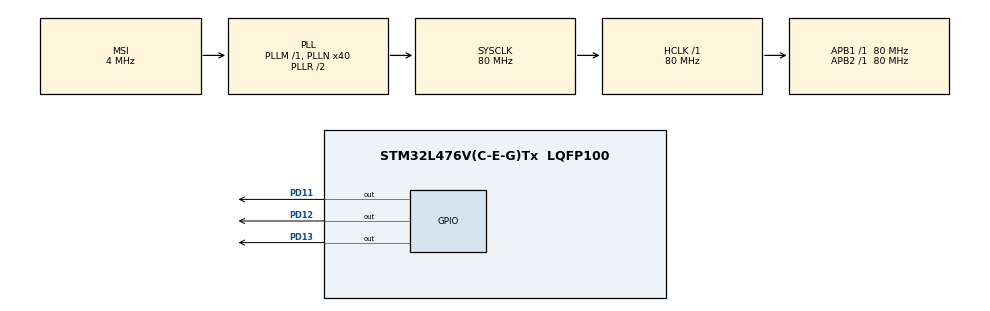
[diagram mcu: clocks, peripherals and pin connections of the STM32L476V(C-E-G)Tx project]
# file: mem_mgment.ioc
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FREERTOS.INCLUDE_xEventGroupSetBitFromISR=1
FREERTOS.INCLUDE_xTimerPendFunctionCall=1
FREERTOS.Tasks01=defaultTask,0,128,StartDefaultTask,Default,NULL,Dynamic,NULL,NULL
FREERTOS.configTOTAL_HEAP_SIZE=5000
FREERTOS.configUSE_NEWLIB_REENTRANT=0
FREERTOS.configUSE_TIMERS=1
Mcu.Family=STM32L4
Mcu.Name=STM32L476V(C-E-G)Tx
Mcu.Package=LQFP100
NVIC.PriorityGroup=NVIC_PRIORITYGROUP_4
NVIC.TIM1_UP_TIM16_IRQn=true\:0\:0\:false\:false\:true\:false\:false\:true
NVIC.TimeBase=TIM1_UP_TIM16_IRQn
NVIC.TimeBaseIP=TIM1
PD11.Signal=GPIO_Output
PD12.Signal=GPIO_Output
PD13.Signal=GPIO_Output
ProjectManager.HeapSize=0x200
ProjectManager.StackSize=0x400
ProjectManager.TargetToolchain=STM32CubeIDE
RCC.AHBFreq_Value=80000000
RCC.APB1Freq_Value=80000000
RCC.APB1TimFreq_Value=80000000
RCC.APB2Freq_Value=80000000
RCC.APB2TimFreq_Value=80000000
RCC.CortexFreq_Value=80000000
RCC.HCLKFreq_Value=80000000
RCC.HSE_VALUE=8000000
RCC.HSI_VALUE=16000000
RCC.LSE_VALUE=32768
RCC.MSI_VALUE=4000000
RCC.PLLN=40
RCC.SYSCLKFreq_VALUE=80000000
RCC.SYSCLKSource=RCC_SYSCLKSOURCE_PLLCLK
RCC.VCOOutputFreq_Value=160000000
VP_FREERTOS_VS_CMSIS_V1.Mode=CMSIS_V1
VP_SYS_VS_tim1.Mode=TIM1
board=custom

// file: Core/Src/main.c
/* USER CODE BEGIN Header */
/**
  ******************************************************************************
  * @file           : main.c
  * @brief          : Main program body
  ******************************************************************************
  * @attention
  *
  * <h2><center>&copy; Copyright (c) 2021 STMicroelectronics.
  * All rights reserved.</center></h2>
  *
  * This software component is licensed by ST under BSD 3-Clause license,
  * the "License"; You may not use this file except in compliance with the
  * License. You may obtain a copy of the License at:
  *                        opensource.org/licenses/BSD-3-Clause
  *
  ******************************************************************************
  */
/* USER CODE END Header */

#include "main.h"
#include "cmsis_os.h"
#include "gpio.h"

/* USER CODE BEGIN PV */
int A __attribute__((section(".ram2"))) = 10U;
/* USER CODE END PV */

void SystemClock_Config(void);
void MX_FREERTOS_Init(void);

int main(void)
{

  /* MCU Configuration--------------------------------------------------------*/

  /* Reset of all peripherals, Initializes the Flash interface and the Systick. */
  HAL_Init();

  /* Configure the system clock */
  SystemClock_Config();

  /* Initialize all configured peripherals */
  MX_GPIO_Init();
  /* USER CODE BEGIN 2 */
  A = 2;
  /* USER CODE END 2 */

  /* Call init function for freertos objects (in freertos.c) */
  MX_FREERTOS_Init();
  /* Start scheduler */
  osKernelStart();

  /* We should never get here as control is now taken by the scheduler */
  /* Infinite loop */
  while (1)
  {

  }
}

void SystemClock_Config(void)
{
  RCC_OscInitTypeDef RCC_OscInitStruct = {0};
  RCC_ClkInitTypeDef RCC_ClkInitStruct = {0};

  /** Initializes the CPU, AHB and APB busses clocks
  */
  RCC_OscInitStruct.OscillatorType = RCC_OSCILLATORTYPE_MSI;
  RCC_OscInitStruct.MSIState = RCC_MSI_ON;
  RCC_OscInitStruct.MSICalibrationValue = 0;
  RCC_OscInitStruct.MSIClockRange = RCC_MSIRANGE_6;
  RCC_OscInitStruct.PLL.PLLState = RCC_PLL_ON;
  RCC_OscInitStruct.PLL.PLLSource = RCC_PLLSOURCE_MSI;
  RCC_OscInitStruct.PLL.PLLM = 1;
  RCC_OscInitStruct.PLL.PLLN = 40;
  RCC_OscInitStruct.PLL.PLLP = RCC_PLLP_DIV7;
  RCC_OscInitStruct.PLL.PLLQ = RCC_PLLQ_DIV2;
  RCC_OscInitStruct.PLL.PLLR = RCC_PLLR_DIV2;
  if (HAL_RCC_OscConfig(&RCC_OscInitStruct) != HAL_OK)
  {
    Error_Handler();
  }
  /** Initializes the CPU, AHB and APB busses clocks
  */
  RCC_ClkInitStruct.ClockType = RCC_CLOCKTYPE_HCLK|RCC_CLOCKTYPE_SYSCLK
                              |RCC_CLOCKTYPE_PCLK1|RCC_CLOCKTYPE_PCLK2;
  RCC_ClkInitStruct.SYSCLKSource = RCC_SYSCLKSOURCE_PLLCLK;
  RCC_ClkInitStruct.AHBCLKDivider = RCC_SYSCLK_DIV1;
  RCC_ClkInitStruct.APB1CLKDivider = RCC_HCLK_DIV1;
  RCC_ClkInitStruct.APB2CLKDivider = RCC_HCLK_DIV1;

  if (HAL_RCC_ClockConfig(&RCC_ClkInitStruct, FLASH_LATENCY_4) != HAL_OK)
  {
    Error_Handler();
  }
  /** Configure the main internal regulator output voltage
  */
  if (HAL_PWREx_ControlVoltageScaling(PWR_REGULATOR_VOLTAGE_SCALE1) != HAL_OK)
  {
    Error_Handler();
  }
}

 /**
  * @brief  Period elapsed callback in non blocking mode
  * @note   This function is called  when TIM1 interrupt took place, inside
  * HAL_TIM_IRQHandler(). It makes a direct call to HAL_IncTick() to increment
  * a global variable "uwTick" used as application time base.
  * @param  htim : TIM handle
  * @retval None
  */
void HAL_TIM_PeriodElapsedCallback(TIM_HandleTypeDef *htim)
{
  if (htim->Instance == TIM1) {
    HAL_IncTick();
  }
}

void Error_Handler(void)
{
}

/************************ (C) COPYRIGHT STMicroelectronics *****END OF FILE****/

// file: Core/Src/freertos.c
/* USER CODE BEGIN Header */
/**
  ******************************************************************************
  * File Name          : freertos.c
  * Description        : Code for freertos applications
  ******************************************************************************
  * @attention
  *
  * <h2><center>&copy; Copyright (c) 2021 STMicroelectronics.
  * All rights reserved.</center></h2>
  *
  * This software component is licensed by ST under Ultimate Liberty license
  * SLA0044, the "License"; You may not use this file except in compliance with
  * the License. You may obtain a copy of the License at:
  *                             www.st.com/SLA0044
  *
  ******************************************************************************
  */
/* USER CODE END Header */

#include "FreeRTOS.h"
#include "task.h"
#include "main.h"
#include "cmsis_os.h"

osThreadId defaultTaskHandle;

void StartDefaultTask(void const * argument);

void MX_FREERTOS_Init(void); /* (MISRA C 2004 rule 8.1) */

/* GetIdleTaskMemory prototype (linked to static allocation support) */
void vApplicationGetIdleTaskMemory( StaticTask_t **ppxIdleTaskTCBBuffer, StackType_t **ppxIdleTaskStackBuffer, uint32_t *pulIdleTaskStackSize );

/* GetTimerTaskMemory prototype (linked to static allocation support) */
void vApplicationGetTimerTaskMemory( StaticTask_t **ppxTimerTaskTCBBuffer, StackType_t **ppxTimerTaskStackBuffer, uint32_t *pulTimerTaskStackSize );

/* USER CODE BEGIN GET_IDLE_TASK_MEMORY */
static StaticTask_t xIdleTaskTCBBuffer;
static StackType_t xIdleStack[configMINIMAL_STACK_SIZE];

void vApplicationGetIdleTaskMemory( StaticTask_t **ppxIdleTaskTCBBuffer, StackType_t **ppxIdleTaskStackBuffer, uint32_t *pulIdleTaskStackSize )
{
  *ppxIdleTaskTCBBuffer = &xIdleTaskTCBBuffer;
  *ppxIdleTaskStackBuffer = &xIdleStack[0];
  *pulIdleTaskStackSize = configMINIMAL_STACK_SIZE;
  /* place for user code */
}
/* USER CODE END GET_IDLE_TASK_MEMORY */

/* USER CODE BEGIN GET_TIMER_TASK_MEMORY */
static StaticTask_t xTimerTaskTCBBuffer;
static StackType_t xTimerStack[configTIMER_TASK_STACK_DEPTH];

void vApplicationGetTimerTaskMemory( StaticTask_t **ppxTimerTaskTCBBuffer, StackType_t **ppxTimerTaskStackBuffer, uint32_t *pulTimerTaskStackSize )
{
  *ppxTimerTaskTCBBuffer = &xTimerTaskTCBBuffer;
  *ppxTimerTaskStackBuffer = &xTimerStack[0];
  *pulTimerTaskStackSize = configTIMER_TASK_STACK_DEPTH;
  /* place for user code */
}
/* USER CODE END GET_TIMER_TASK_MEMORY */

void MX_FREERTOS_Init(void) {

  /* Create the thread(s) */
  /* definition and creation of defaultTask */
  osThreadDef(defaultTask, StartDefaultTask, osPriorityNormal, 0, 128);
  defaultTaskHandle = osThreadCreate(osThread(defaultTask), NULL);

}

void StartDefaultTask(void const * argument)
{
  for(;;)
  {
    osDelay(1);
  }
}

/************************ (C) COPYRIGHT STMicroelectronics *****END OF FILE****/
